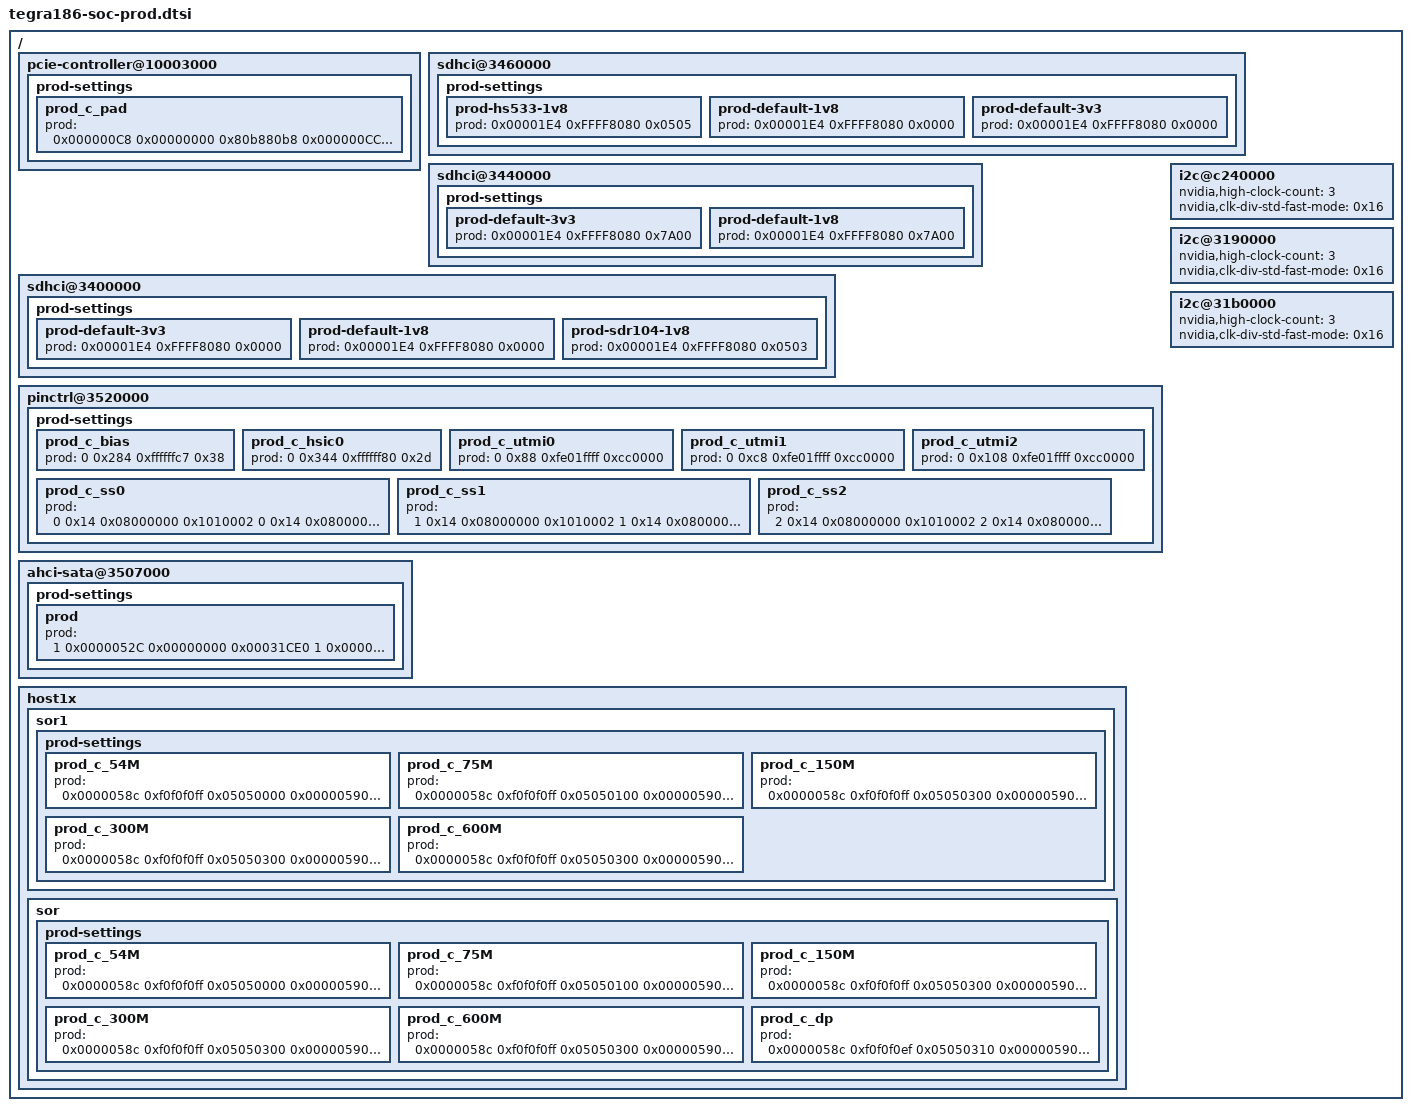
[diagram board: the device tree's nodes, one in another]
/*
 * tegra186-soc-prod.dtsi: Mobile family SoC specific DTSI file with required prod values.
 *
 * Copyright (c) 2016, NVIDIA CORPORATION.  All rights reserved.
 *
 * This program is free software; you can redistribute it and/or modify
 * it under the terms of the GNU General Public License as published by
 * the Free Software Foundation; version 2 of the License.
 *
 * This program is distributed in the hope that it will be useful, but WITHOUT
 * ANY WARRANTY; without even the implied warranty of MERCHANTABILITY or
 * FITNESS FOR A PARTICULAR PURPOSE.  See the GNU General Public License for
 * more details.
 *
 * You should have received a copy of the GNU General Public License along
 * with this program; if not, write to the Free Software Foundation, Inc.,
 * 51 Franklin Street, Fifth Floor, Boston, MA  02110-1301, USA.
 *
 */

/ {

	pcie-controller@10003000 {
		prod-settings {
			prod_c_pad {
				prod = <
					0x000000C8 0x00000000 0x80b880b8	// PADS_REFCLK_CFG0		31:0	 0x80b880b8
					0x000000CC 0x00000000 0x000480b8	// PADS_REFCLK_CFG1		31:0	 0x000480b8
				>;
			};
		};
	};

	sdhci@3460000 {
		prod-settings {
			#prod-cells = <3>;
			prod-hs533-1v8 {
				prod = <0x00001E4 0xFFFF8080 0x0505>;
			};
			prod-default-1v8 {
				prod = <0x00001E4 0xFFFF8080 0x0000>;
			};
			prod-default-3v3 {
				prod = <0x00001E4 0xFFFF8080 0x0000>;
			};
		};
	};

	sdhci@3440000 {
		prod-settings {
			#prod-cells = <3>;
			prod-default-3v3 {
				prod = <0x00001E4 0xFFFF8080 0x7A00>;
			};
			prod-default-1v8 {
				prod = <0x00001E4 0xFFFF8080 0x7A00>;
			};
		};
	};

	sdhci@3400000 {
		prod-settings {
			#prod-cells = <3>;
			prod-default-3v3 {
				prod = <0x00001E4 0xFFFF8080 0x0000>;
			};
			prod-default-1v8 {
				prod = <0x00001E4 0xFFFF8080 0x0000>;
			};
			prod-sdr104-1v8 {
				prod = <0x00001E4 0xFFFF8080 0x0503>;
			};
		};
	};

	pinctrl@3520000 {
		prod-settings {
			#prod-cells = <4>;
			prod_c_bias {
				prod = <0 0x284 0xffffffc7 0x38>;
			};
			prod_c_hsic0 {
				prod = <0 0x344 0xffffff80 0x2d>;
			};
			prod_c_utmi0 {
				prod = <0 0x88 0xfe01ffff 0xcc0000>;
			};
			prod_c_utmi1 {
				prod = <0 0xc8 0xfe01ffff 0xcc0000>;
			};
			prod_c_utmi2 {
				prod = <0 0x108 0xfe01ffff 0xcc0000>;
			};
			prod_c_ss0 {
				prod = <0 0x14 0x08000000 0x1010002
					0 0x14 0x08000000 0x1040032
					0 0x14 0x08000000 0x1070022
					0 0x14 0x08000000 0x1352587
					0 0x14 0x08000000 0x1490fc7
					0 0x14 0x08000000 0x1520001
					0 0x14 0x08000000 0x1533c0f
					0 0x14 0x08000000 0x156c00f
					0 0x14 0x08000000 0x15dff07
					0 0x14 0x08000000 0x15e141a>;
			};
			prod_c_ss1 {
				prod = <1 0x14 0x08000000 0x1010002
					1 0x14 0x08000000 0x1040032
					1 0x14 0x08000000 0x1070022
					1 0x14 0x08000000 0x1352587
					1 0x14 0x08000000 0x1490fc7
					1 0x14 0x08000000 0x1520001
					1 0x14 0x08000000 0x1533c0f
					1 0x14 0x08000000 0x156c00f
					1 0x14 0x08000000 0x15dff07
					1 0x14 0x08000000 0x15e141a>;
			};
			prod_c_ss2 {
				prod = <2 0x14 0x08000000 0x1010002
					2 0x14 0x08000000 0x1040032
					2 0x14 0x08000000 0x1070022
					2 0x14 0x08000000 0x1352587
					2 0x14 0x08000000 0x1490fc7
					2 0x14 0x08000000 0x1520001
					2 0x14 0x08000000 0x1533c0f
					2 0x14 0x08000000 0x156c00f
					2 0x14 0x08000000 0x15dff07
					2 0x14 0x08000000 0x15e141a>;
			};
		};
	};

	ahci-sata@3507000 {
		prod-settings {
			#prod-cells = <4>;
			prod {
				prod = <
					1 0x0000052C 0x00000000 0x00031CE0	// T_SATA0_SPARE_3		31:0
					1 0x00000338 0xEFFFFFFF 0x10000000	// T_SATA0_AHCI_HBA_CYA_1_0     BIT(28)
				>;
			};
		};
	};

	host1x {
		sor1 {
			prod-settings {
				prod_c_54M {
					prod = <
						0x0000058c 0xf0f0f0ff 0x05050000
						0x00000590 0xff0fe0ff 0x00301300
						0x00000598 0x00fff00f 0x38000440
						0x00000138 0x00000000 0x333A3A3A
						0x00000148 0x00000000 0x00000000
						0x000005a0 0xffbf00ff 0x00401000
						0x000005a8 0x00ffffff 0x52000000
					>;
				};
				prod_c_75M {
					prod = <
						0x0000058c 0xf0f0f0ff 0x05050100
						0x00000590 0xff0fe0ff 0x00301300
						0x00000598 0x00fff00f 0x38000440
						0x00000138 0x00000000 0x333A3A3A
						0x00000148 0x00000000 0x00000000
						0x000005a0 0xffbf00ff 0x00404000
						0x000005a8 0x00ffffff 0x42000000
					>;
				};
				prod_c_150M {
					prod = <
						0x0000058c 0xf0f0f0ff 0x05050300
						0x00000590 0xff0fe0ff 0x00301300
						0x00000598 0x00fff00f 0x38000440
						0x00000138 0x00000000 0x333A3A3A
						0x00000148 0x00000000 0x00000000
						0x000005a0 0xffbf00ff 0x00406600
						0x000005a8 0x00ffffff 0x32000000
					>;
				};
				prod_c_300M {
					prod = <
						0x0000058c 0xf0f0f0ff 0x05050300
						0x00000590 0xff0fe0ff 0x00301300
						0x00000598 0x00fff00f 0x3C000440
						0x00000138 0x00000000 0x333F3F3F
						0x00000148 0x00000000 0x001F1F1F
						0x000005a0 0xffbf00ff 0x00406600
						0x000005a8 0x00ffffff 0x32000000
					>;
				};
				prod_c_600M {
					prod = <
						0x0000058c 0xf0f0f0ff 0x05050300
						0x00000590 0xff0fe0ff 0x00301300
						0x00000598 0x00fff00f 0x3C000440
						0x00000138 0x00000000 0x333C3C3C
						0x00000148 0x00000000 0x001F1F1F
						0x000005a0 0xffbf00ff 0x00406600
						0x000005a8 0x00ffffff 0x32000000
					>;
				};
			};
		};

		sor {
			prod-settings {
				prod_c_54M {
					prod = <
						0x0000058c 0xf0f0f0ff 0x05050000
						0x00000590 0xff0fe0ff 0x00301300
						0x00000598 0x00fff00f 0x38000440
						0x00000138 0x00000000 0x333A3A3A
						0x00000148 0x00000000 0x00000000
						0x000005a0 0xffbf00ff 0x00401000
						0x000005a8 0x00ffffff 0x52000000
					>;
				};
				prod_c_75M {
					prod = <
						0x0000058c 0xf0f0f0ff 0x05050100
						0x00000590 0xff0fe0ff 0x00301300
						0x00000598 0x00fff00f 0x38000440
						0x00000138 0x00000000 0x333A3A3A
						0x00000148 0x00000000 0x00000000
						0x000005a0 0xffbf00ff 0x00404000
						0x000005a8 0x00ffffff 0x42000000
					>;
				};
				prod_c_150M {
					prod = <
						0x0000058c 0xf0f0f0ff 0x05050300
						0x00000590 0xff0fe0ff 0x00301300
						0x00000598 0x00fff00f 0x38000440
						0x00000138 0x00000000 0x333A3A3A
						0x00000148 0x00000000 0x00000000
						0x000005a0 0xffbf00ff 0x00406600
						0x000005a8 0x00ffffff 0x32000000
					>;
				};
				prod_c_300M {
					prod = <
						0x0000058c 0xf0f0f0ff 0x05050300
						0x00000590 0xff0fe0ff 0x00301300
						0x00000598 0x00fff00f 0x3C000440
						0x00000138 0x00000000 0x333F3F3F
						0x00000148 0x00000000 0x001F1F1F
						0x000005a0 0xffbf00ff 0x00406600
						0x000005a8 0x00ffffff 0x32000000
					>;
				};
				prod_c_600M {
					prod = <
						0x0000058c 0xf0f0f0ff 0x05050300
						0x00000590 0xff0fe0ff 0x00301300
						0x00000598 0x00fff00f 0x3C000440
						0x00000138 0x00000000 0x333C3C3C
						0x00000148 0x00000000 0x001F1F1F
						0x000005a0 0xffbf00ff 0x00406600
						0x000005a8 0x00ffffff 0x32000000
					>;
				};
				prod_c_dp {
					prod = <
						0x0000058c 0xf0f0f0ef 0x05050310	//SOR_NV_PDISP_SOR_PLL0_0	27:24=ICHPMP		0x05
											//				19:16=FILTER		0x05
											//				11:08=VCOCAP		0x03
											//				04:04=RESISTORSEL	0x01
						0x00000590 0xfcfffeff 0x00000100	//SOR_NV_PDISP_SOR_PLL1_0	25:24=LVDSCM		0x00
											//				08:08=TMDS_TERM		0x01
						0x00000598 0xffffd00f 0x00002440	//SOR_NV_PDISP_SOR_PLL3_0	13:13=PLVVDD_MODE	0x01
											//				11:08=AVDD10_LEVEL	0x04
											//				07:04=AVDD14_LEVEL	0x04
						0x00000070 0x00000000 0x00000000	//SOR_NV_PDISP_SOR_LVDS_0
						0x00000180 0xfffffffe 0x00000001	//SOR_NV_PDISP_SOR_DP_SPARE0_0	00:00=SEQ_ENABLE	0x01
					>;
				};
			};
		};
	};

	i2c@c240000 {
		nvidia,high-clock-count = <3>;
		nvidia,clk-div-std-fast-mode = <0x16>;
	};

	i2c@3190000 {
		nvidia,high-clock-count = <3>;
		nvidia,clk-div-std-fast-mode = <0x16>;
	};

	i2c@31b0000 {
		nvidia,high-clock-count = <3>;
		nvidia,clk-div-std-fast-mode = <0x16>;
	};
};
